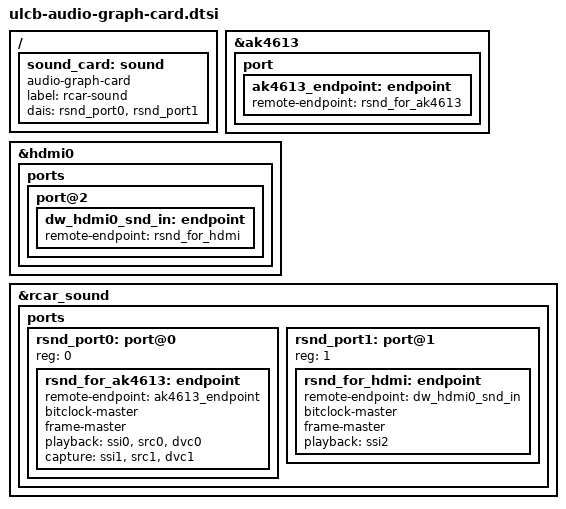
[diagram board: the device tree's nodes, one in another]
/ {
	sound_card: sound {
		compatible = "audio-graph-card";
		label = "rcar-sound";
		dais = <&rsnd_port0  
			&rsnd_port1  
		>;
	};
};
&ak4613 {
	#sound-dai-cells = <0>;
	port {
		ak4613_endpoint: endpoint {
			remote-endpoint = <&rsnd_for_ak4613>;
		};
	};
};
&hdmi0 {
	ports {
		port@2 {
			dw_hdmi0_snd_in: endpoint {
				remote-endpoint = <&rsnd_for_hdmi>;
			};
		};
	};
};
&rcar_sound {
	ports {
		#address-cells = <1>;
		#size-cells = <0>;
		rsnd_port0: port@0 {
			reg = <0>;
			rsnd_for_ak4613: endpoint {
				remote-endpoint = <&ak4613_endpoint>;
				bitclock-master;
				frame-master;
				playback = <&ssi0>, <&src0>, <&dvc0>;
				capture  = <&ssi1>, <&src1>, <&dvc1>;
			};
		};
		rsnd_port1: port@1 {
			reg = <1>;
			rsnd_for_hdmi: endpoint {
				remote-endpoint = <&dw_hdmi0_snd_in>;
				bitclock-master;
				frame-master;
				playback = <&ssi2>;
			};
		};
	};
};
